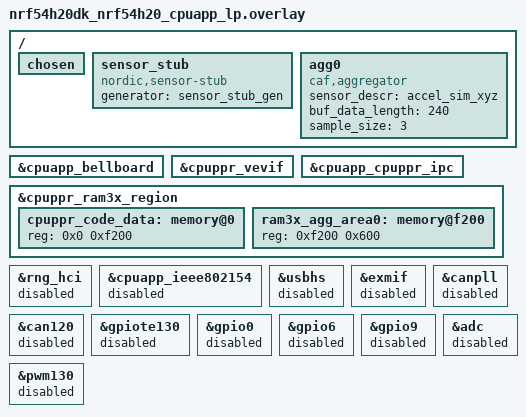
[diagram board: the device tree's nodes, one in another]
/*
 * Copyright (c) 2025 Nordic Semiconductor ASA
 *
 * SPDX-License-Identifier: LicenseRef-Nordic-5-Clause
 */

 /* Replace default ipc0 instance */
/delete-node/ &ipc0;

/ {
	chosen {
		/delete-property/ zephyr,bt-hci;
		/delete-property/ zephyr,ieee802154;
	};

	sensor_stub: sensor_stub {
		compatible = "nordic,sensor-stub";
		generator = "sensor_stub_gen";
		status = "okay";
	};

	agg0: agg0 {
		compatible = "caf,aggregator";
		sensor_descr = "accel_sim_xyz";
		buf_data_length = <240>;
		sample_size = <3>;
	};
};

/* Enabled nodes required by IPC
 * Two mboxes, one for each sides and one ipc instance
 */

&cpuapp_bellboard {
	status = "okay";
};

&cpuppr_vevif {
	status = "okay";
};

ipc0: &cpuapp_cpuppr_ipc {
	status = "okay";
};

&cpuppr_ram3x_region {
	cpuppr_code_data: memory@0 {
		reg = <0x0 0xf200>;
	};

	ram3x_agg_area0: memory@f200 {
		reg = <0xf200 0x600>;
	};
};

/* UART and RAM3 instance used by PPR should be enabled at build time
 * using nordic-ppr snippet.
 */

/* Disable unused devices */

&rng_hci {
	status = "disabled";
};

&cpuapp_ieee802154 {
	status = "disabled";
};

&usbhs {
	status = "disabled";
};

&exmif {
	status = "disabled";
};

&canpll {
	status = "disabled";
};

&can120 {
	status = "disabled";
};

&gpiote130 {
	status = "disabled";
};

&gpio0 {
	status = "disabled";
};

&gpio6 {
	status = "disabled";
};

&gpio9 {
	status = "disabled";
};

&adc {
	status = "disabled";
};

&pwm130 {
	status = "disabled";
};
